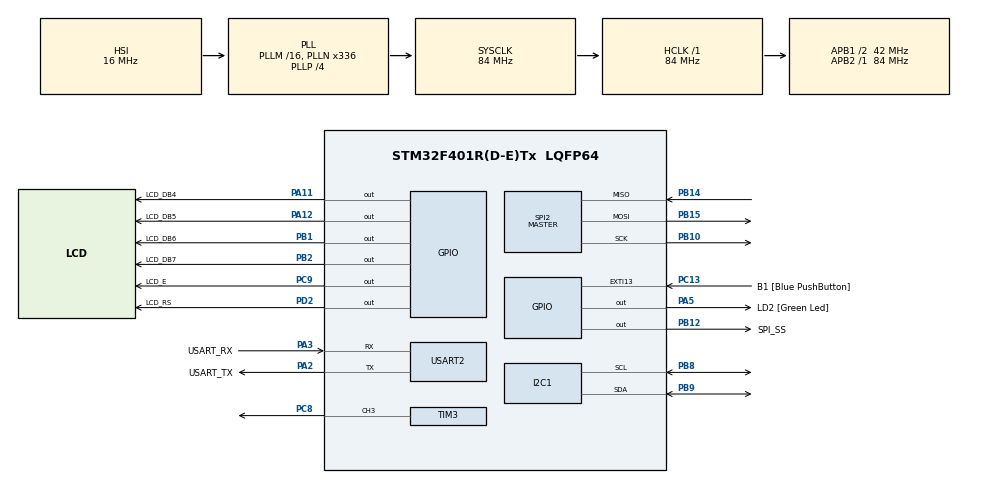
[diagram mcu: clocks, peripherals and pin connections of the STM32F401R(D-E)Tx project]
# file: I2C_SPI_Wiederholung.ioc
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Mcu.Family=STM32F4
PA11.GPIO_Speed=GPIO_SPEED_FREQ_VERY_HIGH
PA2.GPIO_PuPd=GPIO_NOPULL
Dma.SPI2_TX.5.MemDataAlignment=DMA_MDATAALIGN_BYTE
RCC.CortexFreq_Value=84000000
NVIC.I2C1_EV_IRQn=true\:0\:0\:false\:false\:true\:true\:true
SPI2.VirtualType=VM_MASTER
PB10.Mode=Full_Duplex_Master
Dma.USART2_TX.1.MemInc=DMA_MINC_ENABLE
PA14.GPIO_Label=TCK
PA3.GPIO_PuPd=GPIO_NOPULL
PB2.GPIO_Speed=GPIO_SPEED_FREQ_VERY_HIGH
Dma.SPI2_TX.5.Instance=DMA1_Stream4
PA2.GPIO_Speed=GPIO_SPEED_FREQ_LOW
Dma.I2C1_TX.3.PeriphInc=DMA_PINC_DISABLE
PD2.GPIO_Speed=GPIO_SPEED_FREQ_VERY_HIGH
Dma.I2C1_RX.2.MemDataAlignment=DMA_MDATAALIGN_BYTE
PA3.GPIO_Speed=GPIO_SPEED_FREQ_LOW
NVIC.DMA1_Stream4_IRQn=true\:0\:0\:false\:false\:true\:false\:true
PB15.Signal=SPI2_MOSI
Dma.SPI2_RX.4.PeriphInc=DMA_PINC_DISABLE
Dma.I2C1_TX.3.Priority=DMA_PRIORITY_LOW
RCC.SYSCLKSource=RCC_SYSCLKSOURCE_PLLCLK
ProjectManager.StackSize=0x400
Dma.SPI2_TX.5.Priority=DMA_PRIORITY_LOW
Dma.SPI2_RX.4.MemInc=DMA_MINC_ENABLE
PA12.Signal=GPIO_Output
PH0\ -\ OSC_IN.Signal=RCC_OSC_IN
Dma.I2C1_RX.2.PeriphDataAlignment=DMA_PDATAALIGN_BYTE
Dma.I2C1_TX.3.FIFOMode=DMA_FIFOMODE_DISABLE
Dma.USART2_RX.0.Priority=DMA_PRIORITY_LOW
Dma.USART2_RX.0.PeriphDataAlignment=DMA_PDATAALIGN_BYTE
RCC.HCLKFreq_Value=84000000
RCC.APB2TimFreq_Value=84000000
TIM3.Period=100
Dma.USART2_TX.1.Mode=DMA_NORMAL
PB12.PinState=GPIO_PIN_SET
RCC.AHBFreq_Value=84000000
SPI2.BaudRatePrescaler=SPI_BAUDRATEPRESCALER_16
TIM3.Pulse-PWM\ Generation3\ CH3=30
RCC.HSE_VALUE=8000000
PB2.Signal=GPIO_Output
PC13-ANTI_TAMP.Signal=GPXTI13
Dma.I2C1_RX.2.Mode=DMA_NORMAL
PB12.GPIO_Label=SPI_SS
Dma.I2C1_TX.3.MemDataAlignment=DMA_MDATAALIGN_BYTE
Dma.USART2_RX.0.MemDataAlignment=DMA_MDATAALIGN_BYTE
PC14-OSC32_IN.Mode=LSE-External-Oscillator
PB1.GPIO_Speed=GPIO_SPEED_FREQ_VERY_HIGH
PA14.Mode=Serial_Wire
Dma.USART2_TX.1.Instance=DMA1_Stream6
PB14.Mode=Full_Duplex_Master
Dma.I2C1_TX.3.MemInc=DMA_MINC_ENABLE
TIM3.Prescaler=1
PA5.GPIO_PuPd=GPIO_NOPULL
PB1.GPIO_Label=LCD_DB6
Dma.SPI2_TX.5.PeriphInc=DMA_PINC_DISABLE
Dma.USART2_RX.0.Instance=DMA1_Stream5
Dma.I2C1_TX.3.Direction=DMA_MEMORY_TO_PERIPH
NVIC.SPI2_IRQn=true\:0\:0\:false\:false\:true\:true\:true
Dma.I2C1_RX.2.Priority=DMA_PRIORITY_LOW
NVIC.I2C1_ER_IRQn=true\:0\:0\:false\:false\:true\:true\:true
Dma.SPI2_RX.4.Mode=DMA_NORMAL
NVIC.DMA1_Stream7_IRQn=true\:0\:0\:false\:false\:true\:false\:true
Mcu.Package=LQFP64
PB9.Signal=I2C1_SDA
PB1.Signal=GPIO_Output
SPI2.Mode=SPI_MODE_MASTER
Dma.USART2_RX.0.PeriphInc=DMA_PINC_DISABLE
Dma.I2C1_RX.2.PeriphInc=DMA_PINC_DISABLE
Dma.SPI2_TX.5.FIFOMode=DMA_FIFOMODE_DISABLE
USART2.VirtualMode=VM_ASYNC
Dma.USART2_RX.0.FIFOMode=DMA_FIFOMODE_DISABLE
Dma.I2C1_RX.2.Instance=DMA1_Stream0
PA2.GPIO_Label=USART_TX
Dma.I2C1_RX.2.MemInc=DMA_MINC_ENABLE
Dma.Request2=I2C1_RX
Dma.Request1=USART2_TX
RCC.APB1TimFreq_Value=84000000
Dma.Request4=SPI2_RX
Dma.Request3=I2C1_TX
Dma.Request5=SPI2_TX
NVIC.DMA1_Stream0_IRQn=true\:0\:0\:false\:false\:true\:false\:true
SPI2.Direction=SPI_DIRECTION_2LINES
Dma.I2C1_RX.2.FIFOMode=DMA_FIFOMODE_DISABLE
Dma.Request0=USART2_RX
NVIC.DMA1_Stream6_IRQn=true\:0\:0\:false\:false\:true\:false\:true
Dma.SPI2_RX.4.PeriphDataAlignment=DMA_PDATAALIGN_BYTE
VP_TIM3_VS_ClockSourceINT.Mode=Internal
PA12.GPIO_Speed=GPIO_SPEED_FREQ_VERY_HIGH
PA3.Signal=USART2_RX
PA2.GPIO_Mode=GPIO_MODE_AF_PP
PB3.GPIO_Label=SWO
PC15-OSC32_OUT.Mode=LSE-External-Oscillator
Dma.SPI2_TX.5.MemInc=DMA_MINC_ENABLE
Dma.USART2_TX.1.Priority=DMA_PRIORITY_LOW
Dma.SPI2_TX.5.Mode=DMA_NORMAL
Dma.SPI2_RX.4.Priority=DMA_PRIORITY_LOW
Dma.USART2_TX.1.FIFOMode=DMA_FIFOMODE_DISABLE
Dma.SPI2_RX.4.FIFOMode=DMA_FIFOMODE_DISABLE
PC13-ANTI_TAMP.GPIO_PuPd=GPIO_NOPULL
PC9.GPIO_Label=LCD_E
Dma.SPI2_TX.5.PeriphDataAlignment=DMA_PDATAALIGN_BYTE
PC13-ANTI_TAMP.GPIO_Label=B1 [Blue PushButton]
PH1\ -\ OSC_OUT.Mode=HSE-External-Clock-Source
PC8.Signal=S_TIM3_CH3
Dma.USART2_RX.0.Direction=DMA_PERIPH_TO_MEMORY
PA11.GPIO_Label=LCD_DB4
Dma.SPI2_TX.5.Direction=DMA_MEMORY_TO_PERIPH
RCC.APB1CLKDivider=RCC_HCLK_DIV2
PC14-OSC32_IN.Signal=RCC_OSC32_IN
SH.S_TIM3_CH3.0=TIM3_CH3,PWM Generation3 CH3
Dma.USART2_TX.1.PeriphDataAlignment=DMA_PDATAALIGN_BYTE
NVIC.USART2_IRQn=true\:0\:0\:false\:false\:true\:true\:true
PA12.GPIO_Label=LCD_DB5
Dma.USART2_RX.0.Mode=DMA_NORMAL
PA3.Mode=Asynchronous
PA13.Signal=SYS_JTMS-SWDIO
TIM3.Channel-PWM\ Generation3\ CH3=TIM_CHANNEL_3
PH0\ -\ OSC_IN.Mode=HSE-External-Clock-Source
Dma.SPI2_RX.4.Instance=DMA1_Stream3
ProjectManager.TargetToolchain=STM32CubeIDE
NVIC.DMA1_Stream5_IRQn=true\:0\:0\:false\:false\:true\:false\:true
PA3.GPIO_Mode=GPIO_MODE_AF_PP
PB9.Mode=I2C
PC15-OSC32_OUT.Signal=RCC_OSC32_OUT
Dma.I2C1_TX.3.PeriphDataAlignment=DMA_PDATAALIGN_BYTE
PB12.GPIO_Speed=GPIO_SPEED_FREQ_VERY_HIGH
PB10.Signal=SPI2_SCK
PB14.Signal=SPI2_MISO
PA5.Signal=GPIO_Output
PH1\ -\ OSC_OUT.Signal=RCC_OSC_OUT
Dma.USART2_TX.1.PeriphInc=DMA_PINC_DISABLE
board=NUCLEO-F401RE
RCC.VCOOutputFreq_Value=336000000
PB15.Mode=Full_Duplex_Master
Dma.USART2_TX.1.Direction=DMA_MEMORY_TO_PERIPH
RCC.APB2Freq_Value=84000000
PA13.Mode=Serial_Wire
Mcu.Name=STM32F401R(D-E)Tx
Dma.USART2_RX.0.MemInc=DMA_MINC_ENABLE
Dma.SPI2_RX.4.Direction=DMA_PERIPH_TO_MEMORY
PA2.Signal=USART2_TX
PA13.GPIO_Label=TMS
Dma.I2C1_TX.3.Instance=DMA1_Stream7
RCC.48MHZClocksFreq_Value=48000000
PB3.Signal=SYS_JTDO-SWO
RCC.SYSCLKFreq_VALUE=84000000
PA5.GPIO_Label=LD2 [Green Led]
PC13-ANTI_TAMP.GPIO_ModeDefaultEXTI=GPIO_MODE_IT_FALLING
PA11.Signal=GPIO_Output
PA14.Signal=SYS_JTCK-SWCLK
PB2.GPIO_Label=LCD_DB7
ProjectManager.HeapSize=0x200
RCC.HSI_VALUE=16000000
RCC.PLLP=RCC_PLLP_DIV4
PA5.GPIO_Speed=GPIO_SPEED_FREQ_LOW
RCC.PLLQ=7
PC9.GPIO_Speed=GPIO_SPEED_FREQ_VERY_HIGH
NVIC.PriorityGroup=NVIC_PRIORITYGROUP_0
Dma.SPI2_RX.4.MemDataAlignment=DMA_MDATAALIGN_BYTE
PB8.Mode=I2C
RCC.PLLN=336
PB8.Signal=I2C1_SCL
PA2.Mode=Asynchronous
NVIC.DMA1_Stream3_IRQn=true\:0\:0\:false\:false\:true\:false\:true
PC9.Signal=GPIO_Output
Dma.USART2_TX.1.MemDataAlignment=DMA_MDATAALIGN_BYTE
PD2.Signal=GPIO_Output
RCC.APB1Freq_Value=42000000
PA5.GPIO_Mode=GPIO_MODE_OUTPUT_PP
PB12.Signal=GPIO_Output
PD2.GPIO_Label=LCD_RS
Dma.I2C1_TX.3.Mode=DMA_NORMAL
Dma.I2C1_RX.2.Direction=DMA_PERIPH_TO_MEMORY
PA3.GPIO_Label=USART_RX

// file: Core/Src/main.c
/* USER CODE BEGIN Header */
/**
  ******************************************************************************
  * @file           : main.c
  * @brief          : Main program body
  ******************************************************************************
  * @attention
  *
  * <h2><center>&copy; Copyright (c) 2023 STMicroelectronics.
  * All rights reserved.</center></h2>
  *
  * This software component is licensed by ST under BSD 3-Clause license,
  * the "License"; You may not use this file except in compliance with the
  * License. You may obtain a copy of the License at:
  *                        opensource.org/licenses/BSD-3-Clause
  *
  ******************************************************************************
  */
/* USER CODE END Header */
#include "main.h"
#include "dma.h"
#include "i2c.h"
#include "spi.h"
#include "tim.h"
#include "usart.h"
#include "gpio.h"

void SystemClock_Config(void);

int main(void)
{

  /* MCU Configuration--------------------------------------------------------*/

  /* Reset of all peripherals, Initializes the Flash interface and the Systick. */
  HAL_Init();

  /* Configure the system clock */
  SystemClock_Config();

  /* Initialize all configured peripherals */
  MX_GPIO_Init();
  MX_DMA_Init();
  MX_USART2_UART_Init();
  MX_TIM3_Init();
  MX_I2C1_Init();
  MX_SPI2_Init();
  /* USER CODE BEGIN 2 */

//  extern void runLcdTest();
//  runLcdTest();

//  extern void runBmp280I2cTest();
//  runBmp280I2cTest();

//  extern void runBmp280SpiTest();
//  runBmp280SpiTest();

  extern void runSensorDataDisplay();
  runSensorDataDisplay();

  /* USER CODE END 2 */

  /* Infinite loop */
  while (1)
  {

  }
}

void SystemClock_Config(void)
{
  RCC_OscInitTypeDef RCC_OscInitStruct = {0};
  RCC_ClkInitTypeDef RCC_ClkInitStruct = {0};

  /** Configure the main internal regulator output voltage
  */
  __HAL_RCC_PWR_CLK_ENABLE();
  __HAL_PWR_VOLTAGESCALING_CONFIG(PWR_REGULATOR_VOLTAGE_SCALE2);
  /** Initializes the RCC Oscillators according to the specified parameters
  * in the RCC_OscInitTypeDef structure.
  */
  RCC_OscInitStruct.OscillatorType = RCC_OSCILLATORTYPE_HSI;
  RCC_OscInitStruct.HSIState = RCC_HSI_ON;
  RCC_OscInitStruct.HSICalibrationValue = RCC_HSICALIBRATION_DEFAULT;
  RCC_OscInitStruct.PLL.PLLState = RCC_PLL_ON;
  RCC_OscInitStruct.PLL.PLLSource = RCC_PLLSOURCE_HSI;
  RCC_OscInitStruct.PLL.PLLM = 16;
  RCC_OscInitStruct.PLL.PLLN = 336;
  RCC_OscInitStruct.PLL.PLLP = RCC_PLLP_DIV4;
  RCC_OscInitStruct.PLL.PLLQ = 7;
  if (HAL_RCC_OscConfig(&RCC_OscInitStruct) != HAL_OK)
  {
    Error_Handler();
  }
  /** Initializes the CPU, AHB and APB buses clocks
  */
  RCC_ClkInitStruct.ClockType = RCC_CLOCKTYPE_HCLK|RCC_CLOCKTYPE_SYSCLK
                              |RCC_CLOCKTYPE_PCLK1|RCC_CLOCKTYPE_PCLK2;
  RCC_ClkInitStruct.SYSCLKSource = RCC_SYSCLKSOURCE_PLLCLK;
  RCC_ClkInitStruct.AHBCLKDivider = RCC_SYSCLK_DIV1;
  RCC_ClkInitStruct.APB1CLKDivider = RCC_HCLK_DIV2;
  RCC_ClkInitStruct.APB2CLKDivider = RCC_HCLK_DIV1;

  if (HAL_RCC_ClockConfig(&RCC_ClkInitStruct, FLASH_LATENCY_2) != HAL_OK)
  {
    Error_Handler();
  }
}

void Error_Handler(void)
{
  __disable_irq();
  while (1)
  {
  }
}

/************************ (C) COPYRIGHT STMicroelectronics *****END OF FILE****/
